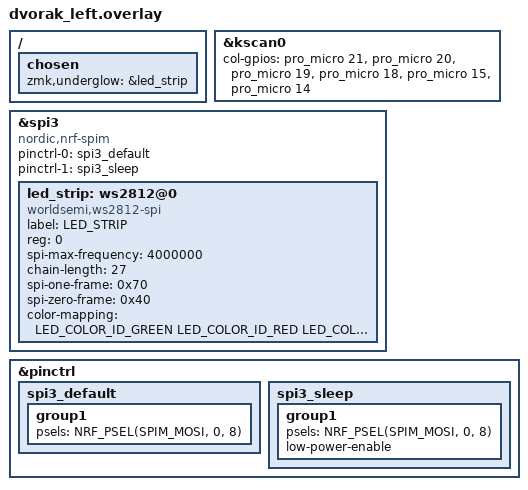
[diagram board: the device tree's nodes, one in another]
/*
 * Copyright (c) 2020 Pete Johanson
 *
 * SPDX-License-Identifier: MIT
 */

#include <dt-bindings/led/led.h>
#include "dvorak.dtsi"

/ {
    chosen {
        zmk,underglow = &led_strip;
    };
};

&kscan0 {
    col-gpios
        = <&pro_micro 21 GPIO_ACTIVE_HIGH>
        , <&pro_micro 20 GPIO_ACTIVE_HIGH>
        , <&pro_micro 19 GPIO_ACTIVE_HIGH>
        , <&pro_micro 18 GPIO_ACTIVE_HIGH>
        , <&pro_micro 15 GPIO_ACTIVE_HIGH>
        , <&pro_micro 14 GPIO_ACTIVE_HIGH>
        ;
};

&spi3 {
    compatible = "nordic,nrf-spim";
    status = "okay";
    pinctrl-0 = <&spi3_default>;
    pinctrl-1 = <&spi3_sleep>;
    pinctrl-names = "default", "sleep";

    led_strip: ws2812@0 {
        compatible = "worldsemi,ws2812-spi";
        label = "LED_STRIP";
        reg = <0>;
        spi-max-frequency = <4000000>;
        chain-length = <27>;
        spi-one-frame = <0x70>;
        spi-zero-frame = <0x40>;
        color-mapping = <LED_COLOR_ID_GREEN LED_COLOR_ID_RED LED_COLOR_ID_BLUE>;
    };
};

&pinctrl {
    spi3_default: spi3_default {
        group1 {
            psels = <NRF_PSEL(SPIM_MOSI, 0, 8)>;
        };
    };

    spi3_sleep: spi3_sleep {
        group1 {
            psels = <NRF_PSEL(SPIM_MOSI, 0, 8)>;
            low-power-enable;
        };
    };
};

